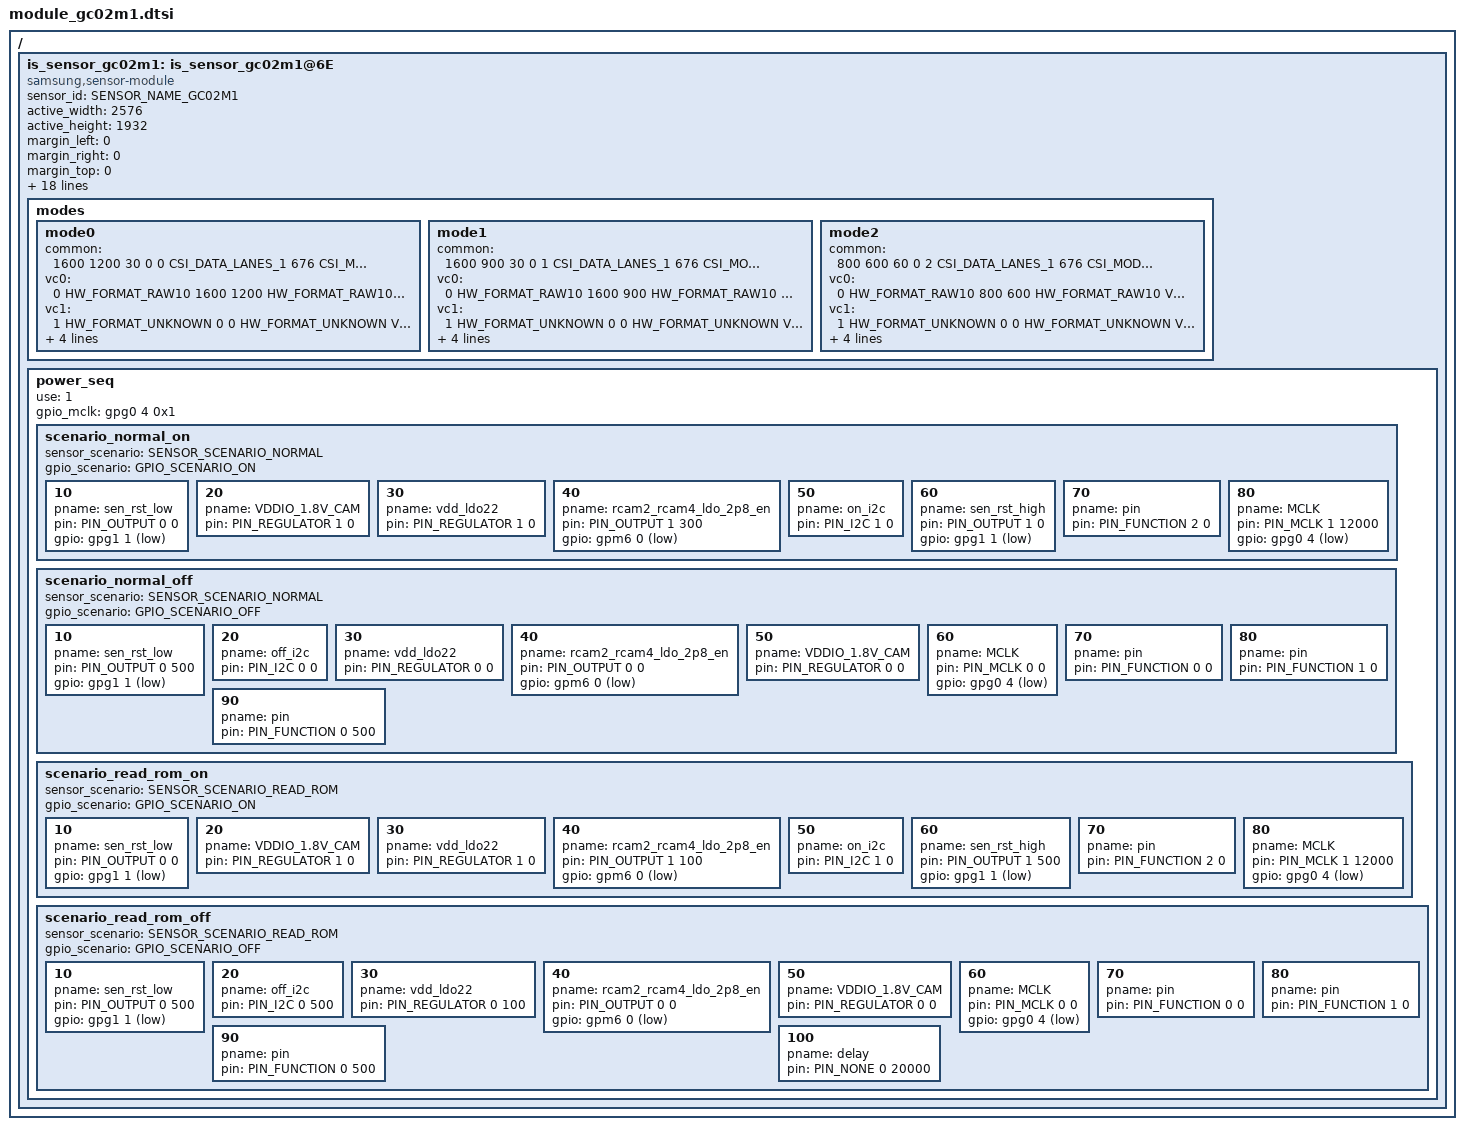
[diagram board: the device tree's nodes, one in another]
/*
 * SAMSUNG EXYNOSxxxx board camera device tree source
 *
 * Copyright (c) 2021 Samsung Electronics Co., Ltd.
 *		http://www.samsung.com
 *
 * This program is free software; you can redistribute it and/or modify
 * it under the terms of the GNU General Public License version 2 as
 * published by the Free Software Foundation.
 */

#include <dt-bindings/camera/exynos_is_dt.h>

/ {
	fragment@camera {
		target-path = "/";
		__overlay__ {
			is_sensor_gc02m1: is_sensor_gc02m1@6E {
				compatible = "samsung,sensor-module";

				/* common */
				sensor_id = <SENSOR_NAME_GC02M1>;
				active_width = <2576>;
				active_height = <1932>;
				margin_left = <0>;
				margin_right = <0>;
				margin_top = <0>;
				margin_bottom = <0>;
				max_framerate = <60>;
				bitwidth = <10>;
				use_retention_mode = <SENSOR_RETENTION_INACTIVE>;
				sensor_maker = "GALAXYCORE";
				sensor_name = "GC02M1";
				setfile_name = "setfile_gc02m1.bin";
				//sensor_module_type = <SENSOR_TYPE_MONO>;

				status = "okay";

				/* board */
				pinctrl-names = "pin0", "pin1", "pin2", "release";
				pinctrl-0 = <>;
				pinctrl-1 = <&sensor_mclk2_out>;
				pinctrl-2 = <&sensor_mclk2_fn>;
				pinctrl-3 = <>;

				position = <2>; /* Rear:0. Front:1, Tele:2 */
				id = <2>; /* is_sensor id */
				mclk_ch = <2>;
				sensor_i2c_ch = <3>; /* SENSOR_CONTROL_I2C3 */

				/* vendor */
				rom_type = <3>; /* ROM_TYPE_OTPROM */
				rom_id = <2>;
				rom_cal_index = <0>;
				/* sensor modes */
				modes {
						/* common = <width, height, fps, settle, mode, lane, speed, interleave, lrte, pd_mode> */
						/* vcX = <map, hwformat, width, height, hwformat, type, width, height> */

					/* 0 : 1600x1200@30fps 4:3 */
					mode0 {
						common = <1600 1200 30 0 0 CSI_DATA_LANES_1 676 CSI_MODE_VC_ONLY LRTE_DISABLE PD_NONE EX_NONE>;
						vc0 = </* in */ 0 HW_FORMAT_RAW10 1600 1200	/* out */ HW_FORMAT_RAW10 VC_NOTHING 0 0>;
						vc1 = </* in */ 1 HW_FORMAT_UNKNOWN 0 0		/* out */ HW_FORMAT_UNKNOWN VC_NOTHING 0 0>;
						vc2 = </* in */ 2 HW_FORMAT_UNKNOWN 0 0		/* out */ HW_FORMAT_UNKNOWN VC_NOTHING 0 0>;
						vc3 = </* in */ 3 HW_FORMAT_UNKNOWN 0 0		/* out */ HW_FORMAT_UNKNOWN VC_NOTHING 0 0>;
					};
					mode1 {
						common = <1600 900 30 0 1 CSI_DATA_LANES_1 676 CSI_MODE_VC_ONLY LRTE_DISABLE PD_NONE EX_NONE>;
						vc0 = </* in */ 0 HW_FORMAT_RAW10 1600 900	/* out */ HW_FORMAT_RAW10 VC_NOTHING 0 0>;
						vc1 = </* in */ 1 HW_FORMAT_UNKNOWN 0 0		/* out */ HW_FORMAT_UNKNOWN VC_NOTHING 0 0>;
						vc2 = </* in */ 2 HW_FORMAT_UNKNOWN 0 0		/* out */ HW_FORMAT_UNKNOWN VC_NOTHING 0 0>;
						vc3 = </* in */ 3 HW_FORMAT_UNKNOWN 0 0		/* out */ HW_FORMAT_UNKNOWN VC_NOTHING 0 0>;
					};
					/* 2 : 800x600@60fps 4:3 */
					mode2 {
						common = <800 600 60 0 2 CSI_DATA_LANES_1 676 CSI_MODE_VC_ONLY LRTE_DISABLE PD_NONE EX_NONE>;
						vc0 = </* in */ 0 HW_FORMAT_RAW10 800 600	/* out */ HW_FORMAT_RAW10 VC_NOTHING 0 0>;
						vc1 = </* in */ 1 HW_FORMAT_UNKNOWN 0 0		/* out */ HW_FORMAT_UNKNOWN VC_NOTHING 0 0>;
						vc2 = </* in */ 2 HW_FORMAT_UNKNOWN 0 0		/* out */ HW_FORMAT_UNKNOWN VC_NOTHING 0 0>;
						vc3 = </* in */ 3 HW_FORMAT_UNKNOWN 0 0		/* out */ HW_FORMAT_UNKNOWN VC_NOTHING 0 0>;
					};
				};

				power_seq {
					use = <1>;
					gpio_mclk = <&gpg0 4 0x1>;
					scenario_normal_on {
						sensor_scenario = <SENSOR_SCENARIO_NORMAL>;
						gpio_scenario = <GPIO_SCENARIO_ON>;

						/* A start node number should be over the 10 for reserved number 0~9. */
						/* pname = "name"; pin = <act value dealy voltage>; gpio = <gpx# # 0x1>; */

						10 { pname = "sen_rst_low"; pin = <PIN_OUTPUT 0 0>; gpio = <&gpg1 1 0x1>; };
						20 { pname = "VDDIO_1.8V_CAM"; pin = <PIN_REGULATOR 1 0>; };
						30 { pname = "vdd_ldo22"; pin = <PIN_REGULATOR 1 0>; };
						40 { pname = "rcam2_rcam4_ldo_2p8_en"; pin = <PIN_OUTPUT 1 300>; gpio = <&gpm6 0 0x1>; };
						50 { pname = "on_i2c"; pin = <PIN_I2C 1 0>; };
						60 { pname = "sen_rst_high"; pin = <PIN_OUTPUT 1 0>; gpio = <&gpg1 1 0x1>; };
						70 { pname = "pin"; pin = <PIN_FUNCTION 2 0>; };
						80 { pname = "MCLK"; pin = <PIN_MCLK 1 12000>; gpio = <&gpg0 4 0x1>; };
					};

					scenario_normal_off {
						sensor_scenario = <SENSOR_SCENARIO_NORMAL>;
						gpio_scenario = <GPIO_SCENARIO_OFF>;

						/* A start node number should be over the 10 for reserved number 0~9. */
						/* pname = "name"; pin = <act value dealy voltage>; gpio = <gpx# # 0x1>; */
						10 { pname = "sen_rst_low"; pin = <PIN_OUTPUT 0 500>; gpio = <&gpg1 1 0x1>; };
						20 { pname = "off_i2c"; pin = <PIN_I2C 0 0>; };
						30 { pname = "vdd_ldo22"; pin = <PIN_REGULATOR 0 0>; };
						40 { pname = "rcam2_rcam4_ldo_2p8_en"; pin = <PIN_OUTPUT 0 0>; gpio = <&gpm6 0 0x1>; };
						50 { pname = "VDDIO_1.8V_CAM"; pin = <PIN_REGULATOR 0 0>; };
						60 { pname = "MCLK"; pin = <PIN_MCLK 0 0>; gpio = <&gpg0 4 0x1>; };
						70 { pname = "pin"; pin = <PIN_FUNCTION 0 0>; };
						80 { pname = "pin"; pin = <PIN_FUNCTION 1 0>; };
						90 { pname = "pin"; pin = <PIN_FUNCTION 0 500>; };
					};

					scenario_read_rom_on {
						sensor_scenario = <SENSOR_SCENARIO_READ_ROM>;
						gpio_scenario = <GPIO_SCENARIO_ON>;

						/* A start node number should be over the 10 for reserved number 0~9. */
						/* pname = "name"; pin = <act value dealy voltage>; gpio = <gpx# # 0x1>; */

						10 { pname = "sen_rst_low"; pin = <PIN_OUTPUT 0 0>; gpio = <&gpg1 1 0x1>; };
						20 { pname = "VDDIO_1.8V_CAM"; pin = <PIN_REGULATOR 1 0>; };
						30 { pname = "vdd_ldo22"; pin = <PIN_REGULATOR 1 0>; };
						40 { pname = "rcam2_rcam4_ldo_2p8_en"; pin = <PIN_OUTPUT 1 100>; gpio = <&gpm6 0 0x1>; };
						50 { pname = "on_i2c"; pin = <PIN_I2C 1 0>; };
						60 { pname = "sen_rst_high"; pin = <PIN_OUTPUT 1 500>; gpio = <&gpg1 1 0x1>; };
						70 { pname = "pin"; pin = <PIN_FUNCTION 2 0>; };
						80 { pname = "MCLK"; pin = <PIN_MCLK 1 12000>; gpio = <&gpg0 4 0x1>; };
					};

					scenario_read_rom_off {
						sensor_scenario = <SENSOR_SCENARIO_READ_ROM>;
						gpio_scenario = <GPIO_SCENARIO_OFF>;

						/* A start node number should be over the 10 for reserved number 0~9. */
						/* pname = "name"; pin = <act value dealy voltage>; gpio = <gpx# # 0x1>; */
						10 { pname = "sen_rst_low"; pin = <PIN_OUTPUT 0 500>; gpio = <&gpg1 1 0x1>; };
						20 { pname = "off_i2c"; pin = <PIN_I2C 0 500>; };
						30 { pname = "vdd_ldo22"; pin = <PIN_REGULATOR 0 100>; };
						40 { pname = "rcam2_rcam4_ldo_2p8_en"; pin = <PIN_OUTPUT 0 0>; gpio = <&gpm6 0 0x1>; };
						50 { pname = "VDDIO_1.8V_CAM"; pin = <PIN_REGULATOR 0 0>; };
						60 { pname = "MCLK"; pin = <PIN_MCLK 0 0>; gpio = <&gpg0 4 0x1>; };
						70 { pname = "pin"; pin = <PIN_FUNCTION 0 0>; };
						80 { pname = "pin"; pin = <PIN_FUNCTION 1 0>; };
						90 { pname = "pin"; pin = <PIN_FUNCTION 0 500>; };
						100 { pname = "delay"; pin = <PIN_NONE 0 20000>; };
					};

				};
			};
		}; /* end of __overlay__ */
	}; /* end of fragment */
}; /* end of root */
